# target register map
Vendor: Vango; Series: TARGET; File version: 1.0
CPU: CM0 r0p0, little endian, no MPU, no FPU, 2 interrupt priority bits
Registers are 32-bit, read-write, reset 0x0 unless marked. A register's access mark holds for its fields unless they carry their own. Offsets are from the block's base; [hi:lo] are bit positions; {n}, {i} and the like mark numbered series.

## PWM_SEL — Timers are 16 bits timers with PWM and capture function.
Base 0x400129F0
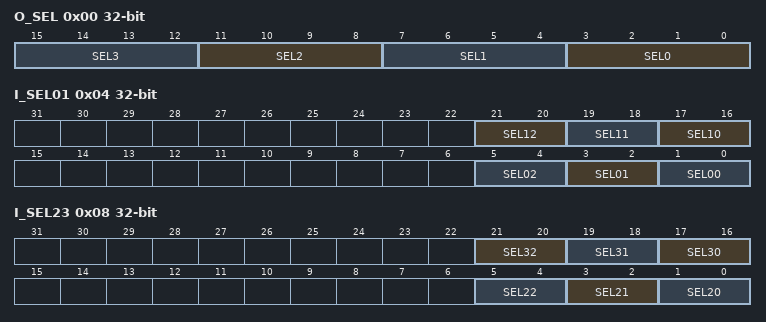
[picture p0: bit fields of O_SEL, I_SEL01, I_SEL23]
0x00 O_SEL — PWM output selection register.
  [all] fields
    0=PWM0_OUT0; 1=PWM0_OUT1; 2=PWM0_OUT2; 4=PWM1_OUT0; 5=PWM1_OUT1; 6=PWM1_OUT2; 8=PWM2_OUT0; 9=PWM2_OUT1; 10=PWM2_OUT2; 12=PWM3_OUT0; 13=PWM3_OUT1; 14=PWM3_OUT2
  [4n+3:4n] SEL{n} (n=0..3) — Output selection register for external output PWM{n}.
0x04 I_SEL01 — Input of PWM0 and PWM1 selection register.
  [all] fields
    {v}=External_PWM{v}_Pin (v=0..3)
  [21:20] SEL12 — IN2 of PWM1 external input control.
  [19:18] SEL11 — IN1 of PWM1 external input control.
  [17:16] SEL10 — IN0 of PWM1 external input control.
  [5:4] SEL02 — IN2 of PWM0 external input control.
  [3:2] SEL01 — IN1 of PWM0 external input control.
  [1:0] SEL00 — IN0 of PWM0 external input control.
0x08 I_SEL23 — Input of PWM2 and PWM3 selection register.
  [all] fields
    {v}=External_PWM{v}_Pin (v=0..3)
  [21:20] SEL32 — IN2 of PWM3 external input control.
  [19:18] SEL31 — IN1 of PWM3 external input control.
  [17:16] SEL30 — IN0 of PWM3 external input control.
  [5:4] SEL22 — IN2 of PWM2 external input control.
  [3:2] SEL21 — IN1 of PWM2 external input control.
  [1:0] SEL20 — IN0 of PWM2 external input control.

## SPI1 — SPI(Serial Peripheral Interface).
Base 0x40011000
Same registers: SPI2 0x40015800, SPI3 0x40016000
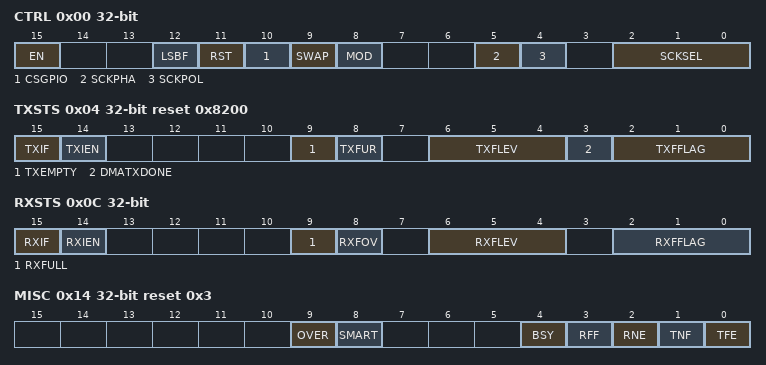
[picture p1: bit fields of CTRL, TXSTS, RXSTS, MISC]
0x00 CTRL — SPI Control Register.
  [15] EN — SPI enable.
  [12] LSBF — SPI LSBF.
  [11] RST — SPI Soft Reset.
  [10] CSGPIO — SPI CS pin is controlled by GPIO or H/W.
  [9] SWAP — SPI MISO/MOSI swap control register.
  [8] MOD — SPI Mode Selection register.
  [5] SCKPHA — SPI clock phase.
  [4] SCKPOL — SPI clock polarity.
  [2:0] SCKSEL — Master mode clock selection
    0=APBCLK_div_2; 1=APBCLK_div_4; 2=APBCLK_div_8; 3=APBCLK_div_16; 4=APBCLK_div_32; 5=APBCLK_div_64; 6=APBCLK_div_128
0x04 TXSTS reset 0x8200 — SPI Transmit Status Register.
  [15] TXIF write-1-clears — SPI Transmit Interrupt flag.
  [14] TXIEN — SPI Transmit Interrupt Enable.
  [9] TXEMPTY ro — Transmit FIFO empty register.
  [8] TXFUR ro — Transmit FIFO under run register.
  [6:4] TXFLEV — Transmit FIFO interrupt level register.
    {v}=Less_than_{v+1} (v=0..7)
  [3] DMATXDONE — DMA Transmit finish flag.
  [2:0] TXFFLAG ro — Transmit FIFO Data Level.
0x08 TXDAT — SPI Transmit FIFO register.
  [7:0] TXD — Write data to SPI Transmit FIFO.
0x0C RXSTS — SPI Receive Status Register.
  [15] RXIF write-1-clears — SPI Receive Interrupt flag.
  [14] RXIEN — SPI Receive Interrupt Enable.
  [9] RXFULL ro — Receive FIFO full register.
  [8] RXFOV ro — Receive FIFO over run register.
  [6:4] RXFLEV — Receive FIFO interrupt level register.
    {v}=Great_Equal_{v+1} (v=0..7)
  [2:0] RXFFLAG ro — Receive FIFO Data Level.
0x10 RXDAT ro — SPI Receive FIFO Register.
  [7:0] RXD — Read data from SPI Receive FIFO.
0x14 MISC reset 0x3 — SPI Misc. Control Register.
  [9] OVER — SPI FIFO Over Write Mode.
  [8] SMART — SPI FIFO SMART Mode Register.
  [4] BSY ro — SPI Controller Busy Flag.
  [3] RFF ro — Receive FIFO Full Flag.
  [2] RNE ro — Receive FIFO Not Empty Flag.
  [1] TNF ro — Transmit FIFO Not Full Flag.
  [0] TFE ro — Transmit FIFO Empty Flag.

## TMR0 — General purpose 32 bits timer, which are used to generate regulate interrupt for CM0.
Base 0x40012800
Same registers: TMR1 0x40012820, TMR2 0x40012840, TMR3 0x40012860
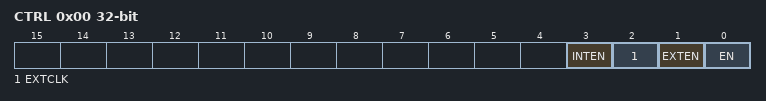
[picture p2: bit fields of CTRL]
0x00 CTRL — Control register of Timer x
  [3] INTEN — Timer x interrupt enable register.
  [2] EXTCLK — Select ext_clk as clock source.
  [1] EXTEN — Select ext_clk as clock enable.
  [0] EN — Timer x enable control register.
0x04 VALUE — Current count register of Timer x
  [31:0] VALUE — Timer x current value register.
0x08 RELOAD — Reload register of Timer x.
  [31:0] RELOAD — Timer x reload value register.
0x0C INTSTS — Interrupt status register of Timer x.
  [0] INTSTS write-1-clears — Timer x interrupt status register.

## UART0 — UART(Universal Asynchronous Receiver/Transmitter).
Base 0x40011800
Same registers: UART1 0x40011820, UART2 0x40011840, UART3 0x40011860, UART4 0x40011880, UART5 0x400118A0
0x00 DATA — UART data register.
  [7:0] DATA — Read: Receive data. Write: Transmit data.
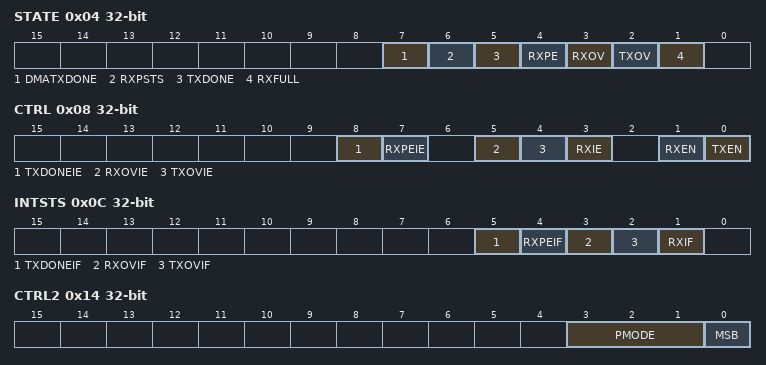
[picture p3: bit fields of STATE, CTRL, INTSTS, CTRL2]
0x04 STATE — UART status register.
  [7] DMATXDONE write-1-clears — DMA Transmit finish flag.
  [6] RXPSTS — Receive parity data flag.
  [5] TXDONE write-1-clears — Transmit done flag.
  [4] RXPE write-1-clears — Receive parity error flag.
  [3] RXOV write-1-clears — Receive buffer overrun flag.
  [2] TXOV write-1-clears — Transmit buffer overrun flag.
  [1] RXFULL — Receive buffer full register.
0x08 CTRL — UART control register.
  [8] TXDONEIE — Transmit done interrupt enable register.
  [7] RXPEIE — Receive parity error interrupt enable register.
  [5] RXOVIE — Receive overrun interrupt enable register.
  [4] TXOVIE — Transmit overrun interrupt enable register.
  [3] RXIE — Receive interrupt enable register.
  [1] RXEN — Receive engine enable register.
  [0] TXEN — Transmit engine enable register.
0x0C INTSTS — UART interrupt status register.
  [5] TXDONEIF write-1-clears — Transmit done flag.
  [4] RXPEIF write-1-clears — Receive parity error flag.
  [3] RXOVIF write-1-clears — Receive buffer overrun flag.
  [2] TXOVIF write-1-clears — Transmit buffer overrun flag.
  [1] RXIF write-1-clears — Receive interrupt flag.
0x10 BAUDDIV — UART baud rate divide register.
  [19:0] BAUDDIV — Baud rate divider register.
0x14 CTRL2 — UART control register 2.
  [3:1] PMODE — Parity mode control register.
    0=Parity_None; 1=Parity_EVEN; 3=Parity_ODD; 5=Parity_L; 7=Parity_H
  [0] MSB — LSB/MSB transmit order control register.
    0=LSB; 1=MSB

## U32K0 — The UART 32K controller is used to receive data via UART protocol.
Base 0x40014100
Same registers: U32K1 0x40014180
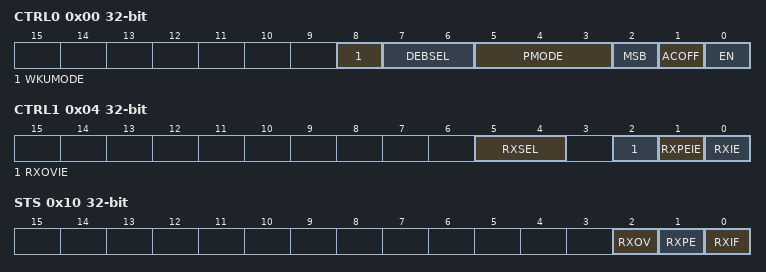
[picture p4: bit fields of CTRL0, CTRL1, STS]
0x00 CTRL0 — UART 32K x control register 0.
  [8] WKUMODE — Wake-up mode control register.
  [7:6] DEBSEL — De-bounce control register.
    0=None; 1=Two_RTCCLK; 2=Three_RTCCLK; 3=Four_RTCCLK
  [5:3] PMODE — Parity mode control register.
    0=Parity_None; 1=Parity_EVEN; 3=Parity_ODD; 5=Parity_L; 7=Parity_H
  [2] MSB — UART receive order control register.
  [1] ACOFF — Auto-calibration off control register.
  [0] EN — UART 32K controller enable register.
0x04 CTRL1 — UART 32K x control register 1.
  [5:4] RXSEL — Receive data select register.
    {v}=From_RX{v} (v=0..3)
  [2] RXOVIE — Receive overrun interrupt/wake-up enable register.
  [1] RXPEIE — Receive parity error interrupt/wake-up enable register.
  [0] RXIE — Receive interrupt/wake-up enable register.
0x08 BAUDDIV reset 0x4B00 — UART 32K x baud rate control register.
  [15:0] BAUDDIV — Baud rate divider register.
0x0C DATA ro reset not defined — UART 32K x receive data buffer.
  [7:0] DATA — Read: Receive data.
0x10 STS — UART 32K x interrupt status register.
  [2] RXOV write-1-clears — Receive buffer overrun flag.
  [1] RXPE write-1-clears — Receive parity error flag.
  [0] RXIF write-1-clears — Receive interrupt flag.
